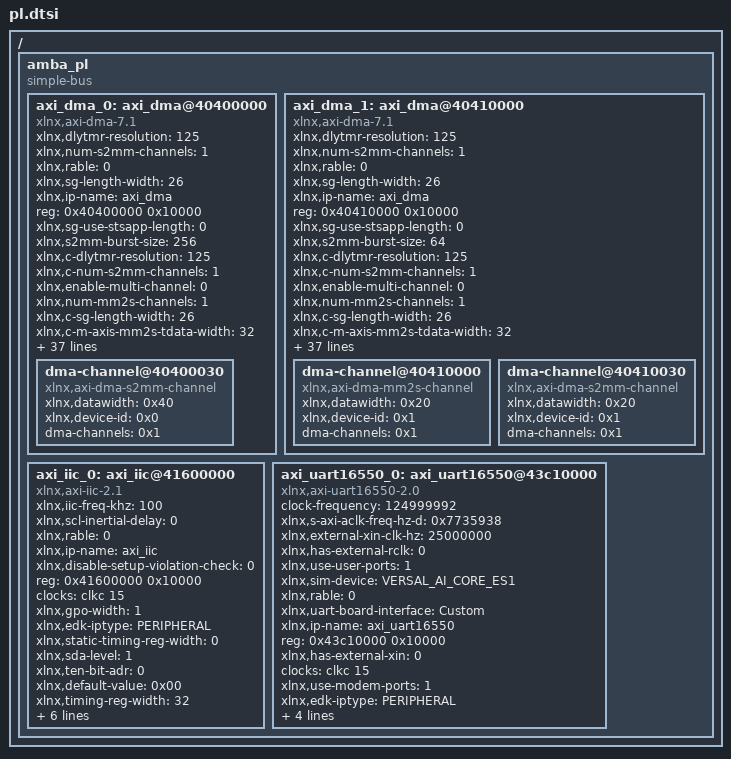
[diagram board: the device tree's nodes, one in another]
/ {
	amba_pl: amba_pl {
		ranges;
		compatible = "simple-bus";
		#address-cells = <1>;
		#size-cells = <1>;
		axi_dma_0: axi_dma@40400000 {
			xlnx,dlytmr-resolution = <125>;
			xlnx,num-s2mm-channels = <1>;
			xlnx,rable = <0>;
			xlnx,sg-length-width = <26>;
			xlnx,ip-name = "axi_dma";
			reg = <0x40400000 0x10000>;
			xlnx,sg-use-stsapp-length = <0>;
			xlnx,s2mm-burst-size = <256>;
			xlnx,c-dlytmr-resolution = <125>;
			xlnx,c-num-s2mm-channels = <1>;
			xlnx,enable-multi-channel = <0>;
			xlnx,num-mm2s-channels = <1>;
			xlnx,c-sg-length-width = <26>;
			compatible = "xlnx,axi-dma-7.1" , "xlnx,axi-dma-1.00.a";
			xlnx,c-m-axis-mm2s-tdata-width = <32>;
			xlnx,c-sg-use-stsapp-length = <0>;
			xlnx,c-s2mm-burst-size = <256>;
			xlnx,mm2s-burst-size = <16>;
			xlnx,c-enable-multi-channel = <0>;
			xlnx,c-num-mm2s-channels = <1>;
			xlnx,include-s2mm-dre = <0>;
			xlnx,c-mm2s-burst-size = <16>;
			status = "okay";
			xlnx,c-include-s2mm-dre = <0>;
			xlnx,include-mm2s-dre = <0>;
			xlnx,name = "axi_dma_0";
			xlnx,c-include-sg = <0>;
			xlnx,c-m-axi-s2mm-data-width = <64>;
			xlnx,include-s2mm-sf = <1>;
			xlnx,c-include-mm2s-dre = <0>;
			xlnx,include-s2mm = <1>;
			clocks = <&clkc 15>, <&clkc 15>;
			xlnx,addrwidth = <0x40>;
			xlnx,c-m-axi-mm2s-data-width = <32>;
			xlnx,edk-iptype = "PERIPHERAL";
			xlnx,c-include-s2mm-sf = <1>;
			xlnx,include-mm2s-sf = <1>;
			clock-names = "m_axi_s2mm_aclk" , "s_axi_lite_aclk";
			xlnx,c-include-s2mm = <1>;
			xlnx,c-addr-width = <64>;
			xlnx,c-single-interface = <0>;
			xlnx,include-mm2s = <0>;
			xlnx,c-s-axis-s2mm-tdata-width = <64>;
			xlnx,s2mm-data-width = <0x40>;
			xlnx,c-include-mm2s-sf = <1>;
			xlnx,prmry-is-aclk-async = <0>;
			xlnx,c-include-mm2s = <0>;
			xlnx,increase-throughput = <0>;
			xlnx,micro-dma = <0>;
			xlnx,mm2s-data-width = <0x20>;
			xlnx,c-prmry-is-aclk-async = <0>;
			xlnx,c-sg-include-stscntrl-strm = <0>;
			xlnx,c-increase-throughput = <0>;
			xlnx,c-micro-dma = <0>;
			dma-channel@40400030 {
				xlnx,datawidth = <0x40>;
				xlnx,device-id = <0x0>;
				compatible = "xlnx,axi-dma-s2mm-channel";
				dma-channels = <0x1>;
			};
		};
		axi_dma_1: axi_dma@40410000 {
			xlnx,dlytmr-resolution = <125>;
			xlnx,num-s2mm-channels = <1>;
			xlnx,rable = <0>;
			xlnx,sg-length-width = <26>;
			xlnx,ip-name = "axi_dma";
			reg = <0x40410000 0x10000>;
			xlnx,sg-use-stsapp-length = <0>;
			xlnx,s2mm-burst-size = <64>;
			xlnx,c-dlytmr-resolution = <125>;
			xlnx,c-num-s2mm-channels = <1>;
			xlnx,enable-multi-channel = <0>;
			xlnx,num-mm2s-channels = <1>;
			xlnx,c-sg-length-width = <26>;
			compatible = "xlnx,axi-dma-7.1" , "xlnx,axi-dma-1.00.a";
			xlnx,c-m-axis-mm2s-tdata-width = <32>;
			xlnx,c-sg-use-stsapp-length = <0>;
			xlnx,c-s2mm-burst-size = <64>;
			xlnx,mm2s-burst-size = <64>;
			xlnx,c-enable-multi-channel = <0>;
			xlnx,c-num-mm2s-channels = <1>;
			xlnx,include-s2mm-dre = <0>;
			xlnx,c-mm2s-burst-size = <64>;
			status = "okay";
			xlnx,c-include-s2mm-dre = <0>;
			xlnx,include-mm2s-dre = <0>;
			xlnx,name = "axi_dma_1";
			xlnx,c-include-sg = <0>;
			xlnx,c-m-axi-s2mm-data-width = <32>;
			xlnx,include-s2mm-sf = <1>;
			xlnx,c-include-mm2s-dre = <0>;
			xlnx,include-s2mm = <1>;
			clocks = <&clkc 15>, <&clkc 15>, <&clkc 15>;
			xlnx,addrwidth = <0x40>;
			xlnx,c-m-axi-mm2s-data-width = <32>;
			xlnx,edk-iptype = "PERIPHERAL";
			xlnx,c-include-s2mm-sf = <1>;
			xlnx,include-mm2s-sf = <1>;
			clock-names = "m_axi_mm2s_aclk" , "m_axi_s2mm_aclk" , "s_axi_lite_aclk";
			xlnx,c-include-s2mm = <1>;
			xlnx,c-addr-width = <64>;
			xlnx,c-single-interface = <0>;
			xlnx,include-mm2s = <1>;
			xlnx,c-s-axis-s2mm-tdata-width = <32>;
			xlnx,s2mm-data-width = <0x20>;
			xlnx,c-include-mm2s-sf = <1>;
			xlnx,prmry-is-aclk-async = <0>;
			xlnx,c-include-mm2s = <1>;
			xlnx,increase-throughput = <0>;
			xlnx,micro-dma = <0>;
			xlnx,mm2s-data-width = <0x20>;
			xlnx,c-prmry-is-aclk-async = <0>;
			xlnx,c-sg-include-stscntrl-strm = <0>;
			xlnx,c-increase-throughput = <0>;
			xlnx,c-micro-dma = <0>;
			dma-channel@40410000 {
				xlnx,datawidth = <0x20>;
				xlnx,device-id = <0x1>;
				compatible = "xlnx,axi-dma-mm2s-channel";
				dma-channels = <0x1>;
			};
			dma-channel@40410030 {
				xlnx,datawidth = <0x20>;
				xlnx,device-id = <0x1>;
				compatible = "xlnx,axi-dma-s2mm-channel";
				dma-channels = <0x1>;
			};
		};
		axi_iic_0: axi_iic@41600000 {
			xlnx,iic-freq-khz = <100>;
			compatible = "xlnx,axi-iic-2.1" , "xlnx,xps-iic-2.00.a";
			xlnx,scl-inertial-delay = <0>;
			xlnx,rable = <0>;
			xlnx,ip-name = "axi_iic";
			xlnx,disable-setup-violation-check = <0>;
			reg = <0x41600000 0x10000>;
			clocks = <&clkc 15>;
			xlnx,gpo-width = <1>;
			xlnx,edk-iptype = "PERIPHERAL";
			xlnx,static-timing-reg-width = <0>;
			xlnx,sda-level = <1>;
			status = "okay";
			clock-names = "s_axi_aclk";
			xlnx,ten-bit-adr = <0>;
			xlnx,default-value = <0x00>;
			xlnx,timing-reg-width = <32>;
			xlnx,iic-board-interface = "Custom";
			xlnx,iic-freq = <100000>;
			xlnx,smbus-pmbus-host = <0>;
			xlnx,sda-inertial-delay = <0>;
			xlnx,name = "axi_iic_0";
			xlnx,axi-aclk-freq-mhz = <0x7735938>;
		};
		axi_uart16550_0: axi_uart16550@43c10000 {
			compatible = "xlnx,axi-uart16550-2.0";
			clock-frequency = <124999992>;
			xlnx,s-axi-aclk-freq-hz-d = <0x7735938>;
			xlnx,external-xin-clk-hz = <25000000>;
			xlnx,has-external-rclk = <0>;
			xlnx,use-user-ports = <1>;
			xlnx,sim-device = "VERSAL_AI_CORE_ES1";
			xlnx,rable = <0>;
			xlnx,uart-board-interface = "Custom";
			xlnx,ip-name = "axi_uart16550";
			reg = <0x43c10000 0x10000>;
			xlnx,has-external-xin = <0>;
			clocks = <&clkc 15>;
			xlnx,use-modem-ports = <1>;
			xlnx,edk-iptype = "PERIPHERAL";
			status = "okay";
			xlnx,external-xin-clk-hz-d = <25>;
			clock-names = "s_axi_aclk";
			xlnx,base-user = <1>;
			xlnx,is-a-16550 = <1>;
			xlnx,name = "axi_uart16550_0";
		};
	};
};
